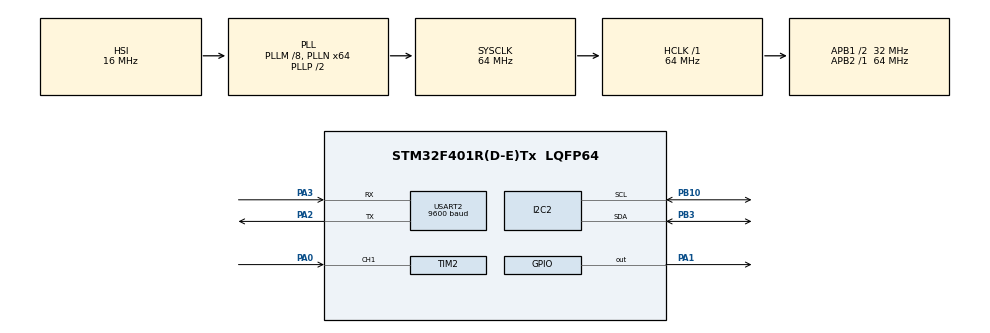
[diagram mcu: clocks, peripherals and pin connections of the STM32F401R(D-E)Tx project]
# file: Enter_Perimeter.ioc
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Mcu.Family=STM32F4
Mcu.Name=STM32F401R(D-E)Tx
Mcu.Package=LQFP64
NVIC.PriorityGroup=NVIC_PRIORITYGROUP_4
NVIC.TIM2_IRQn=true\:0\:0\:false\:false\:true\:true\:true\:true
PA0-WKUP.Signal=S_TIM2_CH1_ETR
PA1.Signal=GPIO_Output
PA2.Mode=Asynchronous
PA2.Signal=USART2_TX
PA3.Mode=Asynchronous
PA3.Signal=USART2_RX
PB10.Mode=I2C
PB10.Signal=I2C2_SCL
PB3.Mode=I2C
PB3.Signal=I2C2_SDA
ProjectManager.HeapSize=0x200
ProjectManager.StackSize=0x400
ProjectManager.TargetToolchain=STM32CubeIDE
RCC.48MHZClocksFreq_Value=32000000
RCC.AHBFreq_Value=64000000
RCC.APB1CLKDivider=RCC_HCLK_DIV2
RCC.APB1Freq_Value=32000000
RCC.APB1TimFreq_Value=64000000
RCC.APB2Freq_Value=64000000
RCC.APB2TimFreq_Value=64000000
RCC.CortexFreq_Value=64000000
RCC.HCLKFreq_Value=64000000
RCC.HSE_VALUE=25000000
RCC.HSI_VALUE=16000000
RCC.LSE_VALUE=32768
RCC.PLLM=8
RCC.PLLN=64
RCC.SYSCLKFreq_VALUE=64000000
RCC.SYSCLKSource=RCC_SYSCLKSOURCE_PLLCLK
RCC.VCOOutputFreq_Value=128000000
SH.S_TIM2_CH1_ETR.0=TIM2_CH1,Input_Capture1_from_TI1
TIM1.Period=6400
TIM1.Prescaler=0
TIM2.Channel-Input_Capture1_from_TI1=TIM_CHANNEL_1
TIM2.ICPolarity_CH1=TIM_INPUTCHANNELPOLARITY_BOTHEDGE
TIM2.Period=10000
TIM2.Prescaler=63
USART2.BaudRate=9600
USART2.VirtualMode=VM_ASYNC
VP_TIM1_VS_ClockSourceINT.Mode=Internal
VP_TIM2_VS_ClockSourceINT.Mode=Internal
board=custom

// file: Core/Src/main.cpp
/* USER CODE BEGIN Header */
/**
  ******************************************************************************
  * @file           : main.c
  * @brief          : Main program body
  ******************************************************************************
  * @attention
  *
  * Copyright (c) 2025 STMicroelectronics.
  * All rights reserved.
  *
  * This software is licensed under terms that can be found in the LICENSE file
  * in the root directory of this software component.
  * If no LICENSE file comes with this software, it is provided AS-IS.
  *
  ******************************************************************************
  */
/* USER CODE END Header */
#include "main.h"
#include <cstdio>
#include "rtc.hpp"

I2C_HandleTypeDef hi2c2;

TIM_HandleTypeDef htim1;
TIM_HandleTypeDef htim2;

UART_HandleTypeDef huart2;

void SystemClock_Config(void);
static void MX_GPIO_Init(void);
static void MX_USART2_UART_Init(void);
static void MX_I2C2_Init(void);
static void MX_TIM2_Init(void);
static void MX_TIM1_Init(void);

int main(void)
{

  /* MCU Configuration--------------------------------------------------------*/

  /* Reset of all peripherals, Initializes the Flash interface and the Systick. */
  HAL_Init();

  /* Configure the system clock */
  SystemClock_Config();

  /* Initialize all configured peripherals */
  MX_GPIO_Init();
  MX_USART2_UART_Init();
  MX_I2C2_Init();
  MX_TIM2_Init();
  MX_TIM1_Init();
  /* USER CODE BEGIN 2 */

  HAL_TIM_Base_Start(&htim1);				//start base timer
  HAL_TIM_IC_Start_IT(&htim2, TIM_CHANNEL_1); //start input capture timer.

  uint8_t num_seconds = 58;
  uint8_t num_minutes = 44;
  uint8_t num_hours = 22;
  uint8_t date_day = SATURDAY;
  uint8_t week_day = 3;
  uint8_t month = MARCH;
  int year = 2025;

  Time_RTC clock(&hi2c2, true, num_seconds, num_minutes, num_hours, date_day, week_day, month, year);

  RTC_Status_E status = clock.rtc_init();
  double distance = 0;
  char message[100];

  /* USER CODE END 2 */

  /* Infinite loop */
  while (1)
  {

  }
}

void SystemClock_Config(void)
{
  RCC_OscInitTypeDef RCC_OscInitStruct = {0};
  RCC_ClkInitTypeDef RCC_ClkInitStruct = {0};

  /** Configure the main internal regulator output voltage
  */
  __HAL_RCC_PWR_CLK_ENABLE();
  __HAL_PWR_VOLTAGESCALING_CONFIG(PWR_REGULATOR_VOLTAGE_SCALE2);

  /** Initializes the RCC Oscillators according to the specified parameters
  * in the RCC_OscInitTypeDef structure.
  */
  RCC_OscInitStruct.OscillatorType = RCC_OSCILLATORTYPE_HSI;
  RCC_OscInitStruct.HSIState = RCC_HSI_ON;
  RCC_OscInitStruct.HSICalibrationValue = RCC_HSICALIBRATION_DEFAULT;
  RCC_OscInitStruct.PLL.PLLState = RCC_PLL_ON;
  RCC_OscInitStruct.PLL.PLLSource = RCC_PLLSOURCE_HSI;
  RCC_OscInitStruct.PLL.PLLM = 8;
  RCC_OscInitStruct.PLL.PLLN = 64;
  RCC_OscInitStruct.PLL.PLLP = RCC_PLLP_DIV2;
  RCC_OscInitStruct.PLL.PLLQ = 4;
  if (HAL_RCC_OscConfig(&RCC_OscInitStruct) != HAL_OK)
  {
    Error_Handler();
  }

  /** Initializes the CPU, AHB and APB buses clocks
  */
  RCC_ClkInitStruct.ClockType = RCC_CLOCKTYPE_HCLK|RCC_CLOCKTYPE_SYSCLK
                              |RCC_CLOCKTYPE_PCLK1|RCC_CLOCKTYPE_PCLK2;
  RCC_ClkInitStruct.SYSCLKSource = RCC_SYSCLKSOURCE_PLLCLK;
  RCC_ClkInitStruct.AHBCLKDivider = RCC_SYSCLK_DIV1;
  RCC_ClkInitStruct.APB1CLKDivider = RCC_HCLK_DIV2;
  RCC_ClkInitStruct.APB2CLKDivider = RCC_HCLK_DIV1;

  if (HAL_RCC_ClockConfig(&RCC_ClkInitStruct, FLASH_LATENCY_2) != HAL_OK)
  {
    Error_Handler();
  }
}

static void MX_I2C2_Init(void)
{

  hi2c2.Instance = I2C2;
  hi2c2.Init.ClockSpeed = 100000;
  hi2c2.Init.DutyCycle = I2C_DUTYCYCLE_2;
  hi2c2.Init.OwnAddress1 = 0;
  hi2c2.Init.AddressingMode = I2C_ADDRESSINGMODE_7BIT;
  hi2c2.Init.DualAddressMode = I2C_DUALADDRESS_DISABLE;
  hi2c2.Init.OwnAddress2 = 0;
  hi2c2.Init.GeneralCallMode = I2C_GENERALCALL_DISABLE;
  hi2c2.Init.NoStretchMode = I2C_NOSTRETCH_DISABLE;
  if (HAL_I2C_Init(&hi2c2) != HAL_OK)
  {
    Error_Handler();
  }

}

static void MX_TIM1_Init(void)
{

  TIM_ClockConfigTypeDef sClockSourceConfig = {0};
  TIM_MasterConfigTypeDef sMasterConfig = {0};

  htim1.Instance = TIM1;
  htim1.Init.Prescaler = 0;
  htim1.Init.CounterMode = TIM_COUNTERMODE_UP;
  htim1.Init.Period = 6400;
  htim1.Init.ClockDivision = TIM_CLOCKDIVISION_DIV1;
  htim1.Init.RepetitionCounter = 0;
  htim1.Init.AutoReloadPreload = TIM_AUTORELOAD_PRELOAD_DISABLE;
  if (HAL_TIM_Base_Init(&htim1) != HAL_OK)
  {
    Error_Handler();
  }
  sClockSourceConfig.ClockSource = TIM_CLOCKSOURCE_INTERNAL;
  if (HAL_TIM_ConfigClockSource(&htim1, &sClockSourceConfig) != HAL_OK)
  {
    Error_Handler();
  }
  sMasterConfig.MasterOutputTrigger = TIM_TRGO_RESET;
  sMasterConfig.MasterSlaveMode = TIM_MASTERSLAVEMODE_DISABLE;
  if (HAL_TIMEx_MasterConfigSynchronization(&htim1, &sMasterConfig) != HAL_OK)
  {
    Error_Handler();
  }

}

static void MX_TIM2_Init(void)
{

  TIM_ClockConfigTypeDef sClockSourceConfig = {0};
  TIM_MasterConfigTypeDef sMasterConfig = {0};
  TIM_IC_InitTypeDef sConfigIC = {0};

  htim2.Instance = TIM2;
  htim2.Init.Prescaler = 63;
  htim2.Init.CounterMode = TIM_COUNTERMODE_UP;
  htim2.Init.Period = 10000;
  htim2.Init.ClockDivision = TIM_CLOCKDIVISION_DIV1;
  htim2.Init.AutoReloadPreload = TIM_AUTORELOAD_PRELOAD_DISABLE;
  if (HAL_TIM_Base_Init(&htim2) != HAL_OK)
  {
    Error_Handler();
  }
  sClockSourceConfig.ClockSource = TIM_CLOCKSOURCE_INTERNAL;
  if (HAL_TIM_ConfigClockSource(&htim2, &sClockSourceConfig) != HAL_OK)
  {
    Error_Handler();
  }
  if (HAL_TIM_IC_Init(&htim2) != HAL_OK)
  {
    Error_Handler();
  }
  sMasterConfig.MasterOutputTrigger = TIM_TRGO_RESET;
  sMasterConfig.MasterSlaveMode = TIM_MASTERSLAVEMODE_DISABLE;
  if (HAL_TIMEx_MasterConfigSynchronization(&htim2, &sMasterConfig) != HAL_OK)
  {
    Error_Handler();
  }
  sConfigIC.ICPolarity = TIM_INPUTCHANNELPOLARITY_BOTHEDGE;
  sConfigIC.ICSelection = TIM_ICSELECTION_DIRECTTI;
  sConfigIC.ICPrescaler = TIM_ICPSC_DIV1;
  sConfigIC.ICFilter = 0;
  if (HAL_TIM_IC_ConfigChannel(&htim2, &sConfigIC, TIM_CHANNEL_1) != HAL_OK)
  {
    Error_Handler();
  }

}

static void MX_USART2_UART_Init(void)
{

  huart2.Instance = USART2;
  huart2.Init.BaudRate = 9600;
  huart2.Init.WordLength = UART_WORDLENGTH_8B;
  huart2.Init.StopBits = UART_STOPBITS_1;
  huart2.Init.Parity = UART_PARITY_NONE;
  huart2.Init.Mode = UART_MODE_TX_RX;
  huart2.Init.HwFlowCtl = UART_HWCONTROL_NONE;
  huart2.Init.OverSampling = UART_OVERSAMPLING_16;
  if (HAL_UART_Init(&huart2) != HAL_OK)
  {
    Error_Handler();
  }

}

static void MX_GPIO_Init(void)
{
  GPIO_InitTypeDef GPIO_InitStruct = {0};

  /* GPIO Ports Clock Enable */
  __HAL_RCC_GPIOA_CLK_ENABLE();
  __HAL_RCC_GPIOB_CLK_ENABLE();

  /*Configure GPIO pin Output Level */
  HAL_GPIO_WritePin(GPIOA, GPIO_PIN_1, GPIO_PIN_RESET);

  /*Configure GPIO pin : PA1 */
  GPIO_InitStruct.Pin = GPIO_PIN_1;
  GPIO_InitStruct.Mode = GPIO_MODE_OUTPUT_PP;
  GPIO_InitStruct.Pull = GPIO_NOPULL;
  GPIO_InitStruct.Speed = GPIO_SPEED_FREQ_LOW;
  HAL_GPIO_Init(GPIOA, &GPIO_InitStruct);

}

void Error_Handler(void)
{
  __disable_irq();
  while (1)
  {
  }
}
